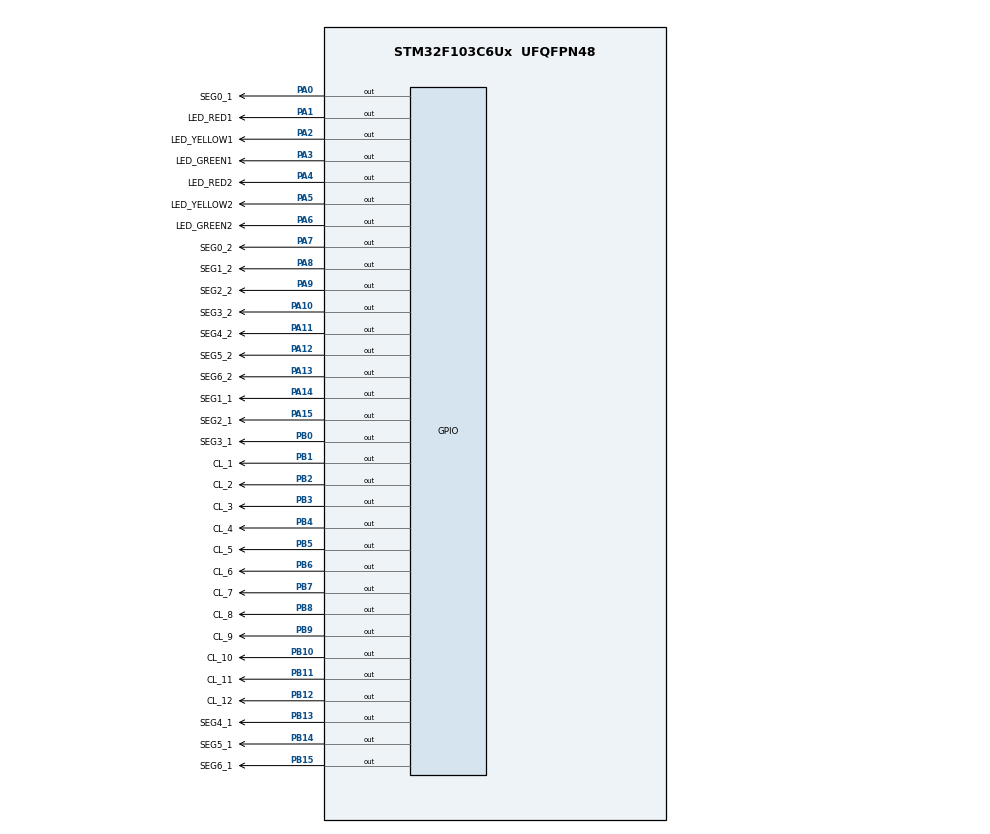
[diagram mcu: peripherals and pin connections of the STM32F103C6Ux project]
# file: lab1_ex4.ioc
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Mcu.Family=STM32F1
Mcu.Name=STM32F103C6Ux
Mcu.Package=UFQFPN48
NVIC.PriorityGroup=NVIC_PRIORITYGROUP_4
PA0-WKUP.GPIO_Label=SEG0_1
PA0-WKUP.Signal=GPIO_Output
PA1.GPIO_Label=LED_RED1
PA1.Signal=GPIO_Output
PA10.GPIO_Label=SEG3_2
PA10.Signal=GPIO_Output
PA11.GPIO_Label=SEG4_2
PA11.Signal=GPIO_Output
PA12.GPIO_Label=SEG5_2
PA12.Signal=GPIO_Output
PA13.GPIO_Label=SEG6_2
PA13.Signal=GPIO_Output
PA14.GPIO_Label=SEG1_1
PA14.Signal=GPIO_Output
PA15.GPIO_Label=SEG2_1
PA15.Signal=GPIO_Output
PA2.GPIO_Label=LED_YELLOW1
PA2.Signal=GPIO_Output
PA3.GPIO_Label=LED_GREEN1
PA3.Signal=GPIO_Output
PA4.GPIO_Label=LED_RED2
PA4.Signal=GPIO_Output
PA5.GPIO_Label=LED_YELLOW2
PA5.Signal=GPIO_Output
PA6.GPIO_Label=LED_GREEN2
PA6.Signal=GPIO_Output
PA7.GPIO_Label=SEG0_2
PA7.Signal=GPIO_Output
PA8.GPIO_Label=SEG1_2
PA8.Signal=GPIO_Output
PA9.GPIO_Label=SEG2_2
PA9.Signal=GPIO_Output
PB0.GPIO_Label=SEG3_1
PB0.Signal=GPIO_Output
PB1.GPIO_Label=CL_1
PB1.Signal=GPIO_Output
PB10.GPIO_Label=CL_10
PB10.Signal=GPIO_Output
PB11.GPIO_Label=CL_11
PB11.Signal=GPIO_Output
PB12.GPIO_Label=CL_12
PB12.Signal=GPIO_Output
PB13.GPIO_Label=SEG4_1
PB13.Signal=GPIO_Output
PB14.GPIO_Label=SEG5_1
PB14.Signal=GPIO_Output
PB15.GPIO_Label=SEG6_1
PB15.Signal=GPIO_Output
PB2.GPIO_Label=CL_2
PB2.Signal=GPIO_Output
PB3.GPIO_Label=CL_3
PB3.Signal=GPIO_Output
PB4.GPIO_Label=CL_4
PB4.Signal=GPIO_Output
PB5.GPIO_Label=CL_5
PB5.Signal=GPIO_Output
PB6.GPIO_Label=CL_6
PB6.Signal=GPIO_Output
PB7.GPIO_Label=CL_7
PB7.Signal=GPIO_Output
PB8.GPIO_Label=CL_8
PB8.Signal=GPIO_Output
PB9.GPIO_Label=CL_9
PB9.Signal=GPIO_Output
ProjectManager.HeapSize=0x200
ProjectManager.StackSize=0x400
ProjectManager.TargetToolchain=STM32CubeIDE
RCC.APB1Freq_Value=8000000
RCC.APB2Freq_Value=8000000
VP_SYS_VS_ND.Mode=No_Debug
board=custom

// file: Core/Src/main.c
/* USER CODE BEGIN Header */
/**
  ******************************************************************************
  * @file           : main.c
  * @brief          : Main program body
  ******************************************************************************
  * @attention
  *
  * <h2><center>&copy; Copyright (c) 2024 STMicroelectronics.
  * All rights reserved.</center></h2>
  *
  * This software component is licensed by ST under BSD 3-Clause license,
  * the "License"; You may not use this file except in compliance with the
  * License. You may obtain a copy of the License at:
  *                        opensource.org/licenses/BSD-3-Clause
  *
  ******************************************************************************
  */
/* USER CODE END Header */
#include "main.h"

/* USER CODE BEGIN Includes */
#include "ex1_test.h"
#include "ex2_test.h"
#include "ex3_test.h"
#include "ex4_test.h"
#include "ex5_test.h"
#include "ex6_test.h"
#include "ex7_test.h"
#include "ex8_test.h"
#include "ex9_test.h"
#include "ex10_test.h"
/* USER CODE END Includes */

void SystemClock_Config(void);
static void MX_GPIO_Init(void);

int main(void)
{

  /* MCU Configuration--------------------------------------------------------*/

  /* Reset of all peripherals, Initializes the Flash interface and the Systick. */
  HAL_Init();

  /* Configure the system clock */
  SystemClock_Config();

  /* Initialize all configured peripherals */
  MX_GPIO_Init();

  /* Infinite loop */
  /* USER CODE BEGIN WHILE */
//  int counter = 0;

//  setNumberOnClock(0);
//  setNumberOnClock(1);
//  setNumberOnClock(2);
  clearAllClock();
  while (1)
  {
	  displayClock(0,0,0);
  }

    /* USER CODE END WHILE */

}

void SystemClock_Config(void)
{
  RCC_OscInitTypeDef RCC_OscInitStruct = {0};
  RCC_ClkInitTypeDef RCC_ClkInitStruct = {0};

  /** Initializes the RCC Oscillators according to the specified parameters
  * in the RCC_OscInitTypeDef structure.
  */
  RCC_OscInitStruct.OscillatorType = RCC_OSCILLATORTYPE_HSI;
  RCC_OscInitStruct.HSIState = RCC_HSI_ON;
  RCC_OscInitStruct.HSICalibrationValue = RCC_HSICALIBRATION_DEFAULT;
  RCC_OscInitStruct.PLL.PLLState = RCC_PLL_NONE;
  if (HAL_RCC_OscConfig(&RCC_OscInitStruct) != HAL_OK)
  {
    Error_Handler();
  }
  /** Initializes the CPU, AHB and APB buses clocks
  */
  RCC_ClkInitStruct.ClockType = RCC_CLOCKTYPE_HCLK|RCC_CLOCKTYPE_SYSCLK
                              |RCC_CLOCKTYPE_PCLK1|RCC_CLOCKTYPE_PCLK2;
  RCC_ClkInitStruct.SYSCLKSource = RCC_SYSCLKSOURCE_HSI;
  RCC_ClkInitStruct.AHBCLKDivider = RCC_SYSCLK_DIV1;
  RCC_ClkInitStruct.APB1CLKDivider = RCC_HCLK_DIV1;
  RCC_ClkInitStruct.APB2CLKDivider = RCC_HCLK_DIV1;

  if (HAL_RCC_ClockConfig(&RCC_ClkInitStruct, FLASH_LATENCY_0) != HAL_OK)
  {
    Error_Handler();
  }
}

static void MX_GPIO_Init(void)
{
  GPIO_InitTypeDef GPIO_InitStruct = {0};

  /* GPIO Ports Clock Enable */
  __HAL_RCC_GPIOA_CLK_ENABLE();
  __HAL_RCC_GPIOB_CLK_ENABLE();

  /*Configure GPIO pin Output Level */
  HAL_GPIO_WritePin(GPIOA, SEG0_1_Pin|LED_RED1_Pin|LED_YELLOW1_Pin|LED_GREEN1_Pin
                          |LED_RED2_Pin|LED_YELLOW2_Pin|LED_GREEN2_Pin|SEG0_2_Pin
                          |SEG1_2_Pin|SEG2_2_Pin|SEG3_2_Pin|SEG4_2_Pin
                          |SEG5_2_Pin|SEG6_2_Pin|SEG1_1_Pin|SEG2_1_Pin, GPIO_PIN_RESET);

  /*Configure GPIO pin Output Level */
  HAL_GPIO_WritePin(GPIOB, SEG3_1_Pin|CL_1_Pin|CL_2_Pin|CL_10_Pin
                          |CL_11_Pin|CL_12_Pin|SEG4_1_Pin|SEG5_1_Pin
                          |SEG6_1_Pin|CL_3_Pin|CL_4_Pin|CL_5_Pin
                          |CL_6_Pin|CL_7_Pin|CL_8_Pin|CL_9_Pin, GPIO_PIN_RESET);

  /*Configure GPIO pins : SEG0_1_Pin LED_RED1_Pin LED_YELLOW1_Pin LED_GREEN1_Pin
                           LED_RED2_Pin LED_YELLOW2_Pin LED_GREEN2_Pin SEG0_2_Pin
                           SEG1_2_Pin SEG2_2_Pin SEG3_2_Pin SEG4_2_Pin
                           SEG5_2_Pin SEG6_2_Pin SEG1_1_Pin SEG2_1_Pin */
  GPIO_InitStruct.Pin = SEG0_1_Pin|LED_RED1_Pin|LED_YELLOW1_Pin|LED_GREEN1_Pin
                          |LED_RED2_Pin|LED_YELLOW2_Pin|LED_GREEN2_Pin|SEG0_2_Pin
                          |SEG1_2_Pin|SEG2_2_Pin|SEG3_2_Pin|SEG4_2_Pin
                          |SEG5_2_Pin|SEG6_2_Pin|SEG1_1_Pin|SEG2_1_Pin;
  GPIO_InitStruct.Mode = GPIO_MODE_OUTPUT_PP;
  GPIO_InitStruct.Pull = GPIO_NOPULL;
  GPIO_InitStruct.Speed = GPIO_SPEED_FREQ_LOW;
  HAL_GPIO_Init(GPIOA, &GPIO_InitStruct);

  /*Configure GPIO pins : SEG3_1_Pin CL_1_Pin CL_2_Pin CL_10_Pin
                           CL_11_Pin CL_12_Pin SEG4_1_Pin SEG5_1_Pin
                           SEG6_1_Pin CL_3_Pin CL_4_Pin CL_5_Pin
                           CL_6_Pin CL_7_Pin CL_8_Pin CL_9_Pin */
  GPIO_InitStruct.Pin = SEG3_1_Pin|CL_1_Pin|CL_2_Pin|CL_10_Pin
                          |CL_11_Pin|CL_12_Pin|SEG4_1_Pin|SEG5_1_Pin
                          |SEG6_1_Pin|CL_3_Pin|CL_4_Pin|CL_5_Pin
                          |CL_6_Pin|CL_7_Pin|CL_8_Pin|CL_9_Pin;
  GPIO_InitStruct.Mode = GPIO_MODE_OUTPUT_PP;
  GPIO_InitStruct.Pull = GPIO_NOPULL;
  GPIO_InitStruct.Speed = GPIO_SPEED_FREQ_LOW;
  HAL_GPIO_Init(GPIOB, &GPIO_InitStruct);

}

void Error_Handler(void)
{
  __disable_irq();
  while (1)
  {
  }
}

/************************ (C) COPYRIGHT STMicroelectronics *****END OF FILE****/
